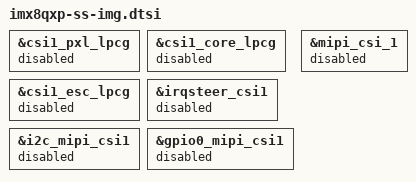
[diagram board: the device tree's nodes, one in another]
// SPDX-License-Identifier: GPL-2.0+
/*
 * Copyright 2019 NXP
 *	Dong Aisheng <aisheng.dong@nxp.com>
 */

&csi1_pxl_lpcg {
	status = "disabled";
};

&csi1_core_lpcg {
	status = "disabled";
};

&csi1_esc_lpcg {
	status = "disabled";
};

&irqsteer_csi1 {
	status = "disabled";
};

&i2c_mipi_csi1 {
	status = "disabled";
};

&gpio0_mipi_csi1 {
	status = "disabled";
};

&mipi_csi_1 {
	status = "disabled";
};
